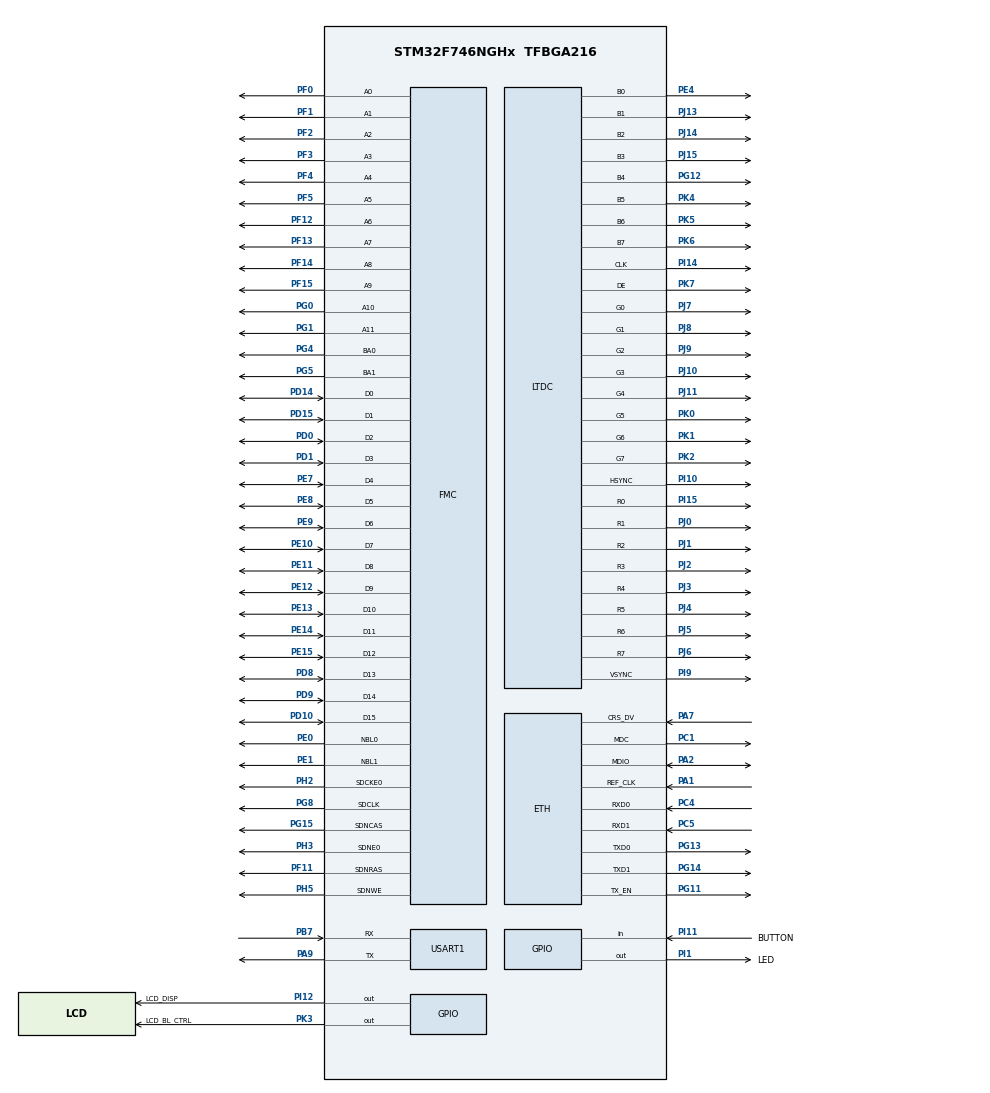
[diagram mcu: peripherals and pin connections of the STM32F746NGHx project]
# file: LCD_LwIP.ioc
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ETH.MACAddr=00\:80\:E1\:00\:00\:44
ETH.MediaInterface=ETH_MEDIA_INTERFACE_RMII
ETH.PhyAddress=0
LTDC.ActiveH=272
LTDC.ActiveW=480
LTDC.Alpha_L0=255
LTDC.Alpha_L1=255
LTDC.BlendingFactor1_L0=LTDC_BLENDING_FACTOR1_PAxCA
LTDC.BlendingFactor1_L1=LTDC_BLENDING_FACTOR1_PAxCA
LTDC.BlendingFactor2_L0=LTDC_BLENDING_FACTOR2_PAxCA
LTDC.BlendingFactor2_L1=LTDC_BLENDING_FACTOR2_PAxCA
LTDC.Green=255
LTDC.HBP=13
LTDC.HFP=32
LTDC.HSync=41
LTDC.ImageHeight_L0=272
LTDC.ImageHeight_L1=272
LTDC.ImageWidth_L0=480
LTDC.ImageWidth_L1=480
LTDC.PixelFormat_L0=LTDC_PIXEL_FORMAT_ARGB1555
LTDC.PixelFormat_L1=LTDC_PIXEL_FORMAT_ARGB1555
LTDC.VSync=10
LTDC.WindowX1_L0=480
LTDC.WindowX1_L1=480
LTDC.WindowY1_L0=272
LTDC.WindowY1_L1=272
LWIP.IP_ADDRESS=192.168.069.010
LWIP.LWIP_DHCP=0
LWIP.NETMASK_ADDRESS=255.255.255.000
LWIP.Version=v2.0.3_Cube
Mcu.Family=STM32F7
Mcu.Name=STM32F746NGHx
Mcu.Package=TFBGA216
NVIC.PriorityGroup=NVIC_PRIORITYGROUP_4
PA1.Mode=RMII
PA1.Signal=ETH_REF_CLK
PA2.Mode=RMII
PA2.Signal=ETH_MDIO
PA7.Mode=RMII
PA7.Signal=ETH_CRS_DV
PA9.Mode=Asynchronous
PA9.Signal=USART1_TX
PB7.Mode=Asynchronous
PB7.Signal=USART1_RX
PC1.Mode=RMII
PC1.Signal=ETH_MDC
PC14/OSC32_IN.Mode=LSE-External-Oscillator
PC14/OSC32_IN.Signal=RCC_OSC32_IN
PC15/OSC32_OUT.Mode=LSE-External-Oscillator
PC15/OSC32_OUT.Signal=RCC_OSC32_OUT
PC4.Mode=RMII
PC4.Signal=ETH_RXD0
PC5.Mode=RMII
PC5.Signal=ETH_RXD1
PD0.Signal=FMC_D2_DA2
PD1.Signal=FMC_D3_DA3
PD10.Signal=FMC_D15_DA15
PD14.Signal=FMC_D0_DA0
PD15.Signal=FMC_D1_DA1
PD8.Signal=FMC_D13_DA13
PD9.Signal=FMC_D14_DA14
PE0.Signal=FMC_NBL0
PE1.Signal=FMC_NBL1
PE10.Signal=FMC_D7_DA7
PE11.Signal=FMC_D8_DA8
PE12.Signal=FMC_D9_DA9
PE13.Signal=FMC_D10_DA10
PE14.Signal=FMC_D11_DA11
PE15.Signal=FMC_D12_DA12
PE4.Mode=RGB888
PE4.Signal=LTDC_B0
PE7.Signal=FMC_D4_DA4
PE8.Signal=FMC_D5_DA5
PE9.Signal=FMC_D6_DA6
PF0.Signal=FMC_A0
PF1.Signal=FMC_A1
PF11.Signal=FMC_SDNRAS
PF12.Signal=FMC_A6
PF13.Signal=FMC_A7
PF14.Signal=FMC_A8
PF15.Signal=FMC_A9
PF2.Signal=FMC_A2
PF3.Signal=FMC_A3
PF4.Signal=FMC_A4
PF5.Signal=FMC_A5
PG0.Signal=FMC_A10
PG1.Signal=FMC_A11
PG11.Mode=RMII
PG11.Signal=ETH_TX_EN
PG12.Mode=RGB888
PG12.Signal=LTDC_B4
PG13.Mode=RMII
PG13.Signal=ETH_TXD0
PG14.Mode=RMII
PG14.Signal=ETH_TXD1
PG15.Signal=FMC_SDNCAS
PG4.Signal=FMC_A14_BA0
PG5.Signal=FMC_A15_BA1
PG8.Signal=FMC_SDCLK
PH0/OSC_IN.Mode=HSE-External-Oscillator
PH0/OSC_IN.Signal=RCC_OSC_IN
PH1/OSC_OUT.Mode=HSE-External-Oscillator
PH1/OSC_OUT.Signal=RCC_OSC_OUT
PH2.Mode=SdramChipSelect1_1
PH2.Signal=FMC_SDCKE0
PH3.Mode=SdramChipSelect1_1
PH3.Signal=FMC_SDNE0
PH5.Signal=FMC_SDNWE
PI1.GPIO_Label=LED
PI1.Signal=GPIO_Output
PI10.Mode=RGB888
PI10.Signal=LTDC_HSYNC
PI11.GPIO_Label=BUTTON
PI11.Signal=GPIO_Input
PI12.GPIO_Label=LCD_DISP
PI12.Signal=GPIO_Output
PI14.Mode=RGB888
PI14.Signal=LTDC_CLK
PI15.Mode=RGB888
PI15.Signal=LTDC_R0
PI9.Mode=RGB888
PI9.Signal=LTDC_VSYNC
PJ0.Mode=RGB888
PJ0.Signal=LTDC_R1
PJ1.Mode=RGB888
PJ1.Signal=LTDC_R2
PJ10.Mode=RGB888
PJ10.Signal=LTDC_G3
PJ11.Mode=RGB888
PJ11.Signal=LTDC_G4
PJ13.Mode=RGB888
PJ13.Signal=LTDC_B1
PJ14.Mode=RGB888
PJ14.Signal=LTDC_B2
PJ15.Mode=RGB888
PJ15.Signal=LTDC_B3
PJ2.Mode=RGB888
PJ2.Signal=LTDC_R3
PJ3.Mode=RGB888
PJ3.Signal=LTDC_R4
PJ4.Mode=RGB888
PJ4.Signal=LTDC_R5
PJ5.Mode=RGB888
PJ5.Signal=LTDC_R6
PJ6.Mode=RGB888
PJ6.Signal=LTDC_R7
PJ7.Mode=RGB888
PJ7.Signal=LTDC_G0
PJ8.Mode=RGB888
PJ8.Signal=LTDC_G1
PJ9.Mode=RGB888
PJ9.Signal=LTDC_G2
PK0.Mode=RGB888
PK0.Signal=LTDC_G5
PK1.Mode=RGB888
PK1.Signal=LTDC_G6
PK2.Mode=RGB888
PK2.Signal=LTDC_G7
PK3.GPIO_Label=LCD_BL_CTRL
PK3.Signal=GPIO_Output
PK4.Mode=RGB888
PK4.Signal=LTDC_B5
PK5.Mode=RGB888
PK5.Signal=LTDC_B6
PK6.Mode=RGB888
PK6.Signal=LTDC_B7
PK7.Mode=RGB888
PK7.Signal=LTDC_DE
ProjectManager.HeapSize=0x200
ProjectManager.StackSize=0x400
ProjectManager.TargetToolchain=SW4STM32
RCC.AHBFreq_Value=200000000
RCC.APB1CLKDivider=RCC_HCLK_DIV4
RCC.APB1Freq_Value=50000000
RCC.APB1TimFreq_Value=100000000
RCC.APB2CLKDivider=RCC_HCLK_DIV2
RCC.APB2Freq_Value=100000000
RCC.APB2TimFreq_Value=200000000
RCC.CortexFreq_Value=200000000
RCC.HCLKFreq_Value=200000000
RCC.HSE_VALUE=25000000
RCC.HSI_VALUE=16000000
RCC.PLLM=25
RCC.PLLN=400
RCC.PLLSAIR=5
RCC.PLLSAIRDiv=RCC_PLLSAIDIVR_4
RCC.PLLSourceVirtual=RCC_PLLSOURCE_HSE
RCC.SYSCLKFreq_VALUE=200000000
RCC.SYSCLKSource=RCC_SYSCLKSOURCE_PLLCLK
RCC.USBFreq_Value=200000000
RCC.VCOOutputFreq_Value=400000000
SH.FMC_A0.0=FMC_A0,12b-sda1
SH.FMC_A1.0=FMC_A1,12b-sda1
SH.FMC_A10.0=FMC_A10,12b-sda1
SH.FMC_A11.0=FMC_A11,12b-sda1
SH.FMC_A14_BA0.0=FMC_BA0,FourSdramBanks1
SH.FMC_A15_BA1.0=FMC_BA1,FourSdramBanks1
SH.FMC_A2.0=FMC_A2,12b-sda1
SH.FMC_A3.0=FMC_A3,12b-sda1
SH.FMC_A4.0=FMC_A4,12b-sda1
SH.FMC_A5.0=FMC_A5,12b-sda1
SH.FMC_A6.0=FMC_A6,12b-sda1
SH.FMC_A7.0=FMC_A7,12b-sda1
SH.FMC_A8.0=FMC_A8,12b-sda1
SH.FMC_A9.0=FMC_A9,12b-sda1
SH.FMC_D0_DA0.0=FMC_D0,sd-16b-d1
SH.FMC_D10_DA10.0=FMC_D10,sd-16b-d1
SH.FMC_D11_DA11.0=FMC_D11,sd-16b-d1
SH.FMC_D12_DA12.0=FMC_D12,sd-16b-d1
SH.FMC_D13_DA13.0=FMC_D13,sd-16b-d1
SH.FMC_D14_DA14.0=FMC_D14,sd-16b-d1
SH.FMC_D15_DA15.0=FMC_D15,sd-16b-d1
SH.FMC_D1_DA1.0=FMC_D1,sd-16b-d1
SH.FMC_D2_DA2.0=FMC_D2,sd-16b-d1
SH.FMC_D3_DA3.0=FMC_D3,sd-16b-d1
SH.FMC_D4_DA4.0=FMC_D4,sd-16b-d1
SH.FMC_D5_DA5.0=FMC_D5,sd-16b-d1
SH.FMC_D6_DA6.0=FMC_D6,sd-16b-d1
SH.FMC_D7_DA7.0=FMC_D7,sd-16b-d1
SH.FMC_D8_DA8.0=FMC_D8,sd-16b-d1
SH.FMC_D9_DA9.0=FMC_D9,sd-16b-d1
SH.FMC_NBL0.0=FMC_NBL0,Sd2ByteEnable1
SH.FMC_NBL1.0=FMC_NBL1,Sd2ByteEnable1
SH.FMC_SDCLK.0=FMC_SDCLK,12b-sda1
SH.FMC_SDNCAS.0=FMC_SDNCAS,12b-sda1
SH.FMC_SDNRAS.0=FMC_SDNRAS,12b-sda1
SH.FMC_SDNWE.0=FMC_SDNWE,12b-sda1
USART1.VirtualMode=VM_ASYNC
USART1.VirtualMode-Asynchronous=VM_ASYNC
USART1.WordLength=WORDLENGTH_8B
VP_DMA2D_VS_DMA2D.Mode=DMA2D_Activate
VP_LWIP_VS_Enabled.Mode=Enabled
board=STM32F746G-DISCO

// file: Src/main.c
/**
= Titel van het project: Game of Life =

== door:  Vermeulen Gijs ==

== Korte beschrijving ==
Conway's game of life soms wel life genoemd is een cellulaire automaat.

Deze bevind zich in een 2 dimensionaal raster met vierkante "cellen" die levend of dood kunnen zijn
en die zich volgens vastgelegde regels ontwikkelen en daarbij patronen kunnen vormen.

Dit algoritme volgt 3 hoofd regels:
	Als een levende cel door 2 of 3 levende buurcellen omgeven wordt blijft deze cel leven
	Als een levende cel door 4 of meer levende buurcellen omgeven wordt gaat deze cel dood
	Als een dode cel door precies 3 gekleurde buurcellen omgeven wordt gaat deze cel leven

Dit algoritme heb ik in labview gemaakt.
Het labview programma gaat als server werken en het embedded systeem gaat hier via TCP/IP data van halen en weergeven op zijn LCD.
De client kan ook zelf dingen naar de server sturen.
	- via knoppen kunnen een aantal vaste patronen verstuurd worden
	- via de "eigen "knop" kan men iets in de server applicatie tekenen of als text string ingeven.
Oneindig veel plezier !
== Libs, compiler en apps ==

 - lwip version LwIP V2.0.3 version ( de versie van uit het labo bestand )
 - CubeMX version 4.27.0
 - System workbench (SW4STM32) FW_F7_V1.15.0
 - Labview 2013

== Bestanden aangemaakt/aangepast ==

   Aangepaste bestanden:
	- LCD_LwIP  ( gestart van het bestand op canvas )
   Aangemaakte bestanden:
	- Labview programma ( server )
	- alle afbeeldingen gebruikt in het project ( paint )

== Opmerkingen ==
voor het labview programma te starten :
					- kan op zich werken :
						- zie dat communicatie uit staat
						- zie dat milliseconds to wait minstens op 500 staat
						- begin het programma door via het keuze menu data in de array te sturen.
						( de keuzes :init, next , niks en communicatie versturen geen data in de array !)
						- ( hij zet data altijd in het midden van de array )
						- ( bij eigen zet hij de data in het begin via de eigen array in het programma
						- LET THE GAME BEGIN !
					- als server :
						- zie dat communicatie aan staat ( knop )
						- zie dat milliseconds to wait op 0 staat
						- zie dat grote op 20 ( server verstuurd 1 info pakket en 1 data pakket )tot 30 staat ( server verstuurd 1 info pakket en 2 data pakketten )
						( als we te groot gaan kan LWIP de data niet aan en verliezen we pakketten of worden pakketten random genegeerd )
						- zet de client nu aan ( hij connecteerd beter als je voor op start te klikken eerst is op stop klikt )
						- op de client kan je terwijl het programma bezig is data in de array sturen via de knoppen.
						- De server gaat maar 1 keer rekening houden met de data dat een knop verstuurd ookal blijft de knop actief ( de knop op de LCD licht groen op)
						- je kan maar 1 knop actief hebben tegelijkertijd
						- ( door nog eens op de knop te duwen desactiveer je de knop )
						- soms als je te laat drukt zal er nog een fase tussen zitten ( hangt af van de timing wanneer je klikt en wanneer de pakketten verstuurd worden)
						- LET THE FUN BEGIN

De server loopt altijd 1 fase voor op de client.
( als de client zegt trying to connect kan je best eens op stop drukken en dan terug op start drukken , ik heb ondervonden dat hij dan direct binnen raakt )

== Bronvermeldingen ==
https://en.wikipedia.org/wiki/Conway%27s_Game_of_Life

== Optioneel: Extra's ==

  */
#include "main.h"
#include "stm32f7xx_hal.h"
#include "lwip.h"
#include <errno.h>
#include <sys/stat.h>
#include <sys/times.h>
#include <sys/unistd.h>
#include <tcp.h>

/* USER CODE BEGIN Includes */

#include<stdio.h>
#include<stdlib.h>
#include<stdint.h>
#include "stm32746g_discovery.h"
#include "stm32746g_discovery_lcd.h"
#include "stm32746g_discovery_sdram.h"
#include "stm32746g_discovery_ts.h"

// image data
#include "stop_knop_data.h"
#include "start_KNOP_data.h"
#include "levende_cel_data.h"
#include "dode_cel_data.h"
#include "Block_knop_inactive_data.h"
#include "custom_knop_inactive_data.h"
#include "GLIDER_knop_inactive_data.h"
#include "knop_active_data.h"
#include "LWSS_knop_inactive_data.h"
#include "PULSAR_knop_inactive_data.h"
#include "INIT_knop_inactive_data.h"
/* USER CODE END Includes */

DMA2D_HandleTypeDef hdma2d;

LTDC_HandleTypeDef hltdc;

UART_HandleTypeDef huart1;

SDRAM_HandleTypeDef hsdram1;

/* USER CODE BEGIN PV */
/* Private variables ---------------------------------------------------------*/

// globale variabelen

char x_tcp_buffer[1024];
uint8_t uc_Closed = 0;
uint8_t uc_Gcounter = 0;

uint8_t uc_start = 1;
uint8_t uc_Data = 0;
uint16_t us_Glen = 0;
int16_t us_Ga = 0;			// als er meerdere data paketten zijn de x waarde bijhouden
int16_t us_Gj = 0;			// als er meerdere data paketten zijn de y waarde bijhouden

// defines

#define x10  10
#define x85  85
#define y20  20
#define y60  60
#define y100 100
#define y140 140
#define y180 180
#define y220 220

#define PORT_SERVER 20
#define PORT_CLIENT 40000

/* USER CODE END PV */

void SystemClock_Config( void );
static void MX_GPIO_Init( void );
static void MX_LTDC_Init( void );
static void MX_USART1_UART_Init( void );
static void MX_DMA2D_Init( void );
static void MX_FMC_Init( void );

/* USER CODE BEGIN PFP */
/* Private function prototypes -----------------------------------------------*/
static void prvdraw( uint16_t, uint8_t );
static uint8_t ucomzetten( uint16_t );

/* ---------------------------------------------------------------------------------*/
/* USER CODE END PFP */

/* USER CODE BEGIN 0 */

int16_t _write( int16_t us_file, char *ptr, int16_t us_len1 )
{
    HAL_StatusTypeDef xStatus;
    switch (us_file) {
    case STDOUT_FILENO: /*stdout*/
		xStatus = HAL_UART_Transmit(&huart1, (uint8_t*)ptr, us_len1, HAL_MAX_DELAY);
		if ( xStatus != HAL_OK ) {
			errno = EIO;
			return -1;
		}
        break;
    case STDERR_FILENO: /* stderr */
		xStatus = HAL_UART_Transmit(&huart1, (uint8_t*)ptr, us_len1, HAL_MAX_DELAY);
		if ( xStatus != HAL_OK ) {
			errno = EIO;
			return -1;
		}
        break;
    default:
        errno = EBADF;
        return -1;
    }
    return us_len1;
}
/* ---------------------------------------------------------------------------------*/
static void Close (struct tcp_pcb *pcb )
{

    tcp_close(pcb);
    BSP_LCD_ClearStringLine(0);
	BSP_LCD_DisplayStringAt(0, 0, (uint8_t*) "Disconnected", CENTER_MODE);
	// globale waardes goed zetten voor de volgende connectie
    uc_Gcounter = 0;
    us_Glen = 0;
    us_Ga = 0;
    us_Gj = 0;
    uc_start = 1;
}
/* ---------------------------------------------------------------------------------*/
static err_t Ontvangen( void *arg, struct tcp_pcb *pcb, struct pbuf *p, err_t err )
{
	uint16_t us_Teller;
    uint16_t us_len;
    char *pc;
    uc_Gcounter++;
    LWIP_UNUSED_ARG( arg );
    if ( err == ERR_OK && p != NULL )			// er is geen error en er zit data in de databuffer
    {
    	tcp_recved( pcb, p->tot_len );
    	printf("stuur ack naar server\r\n");
    	pc = (char *)p->payload;
    	us_len =p->tot_len;
    	for( us_Teller = 0; us_Teller<us_len; us_Teller++ )
    	{
    		x_tcp_buffer[us_Teller] = pc[us_Teller];
    	}
    	prvdraw(us_len, uc_Gcounter);
    }
    else									  // stel er gaat iets mis ( een error bv ) maak de buffer vrij
    {
    	pbuf_free( p );
    }

    pbuf_free( p );

    if( err == ERR_OK && p == NULL )			// er is geen error en de databuffer is leeg gemaakt sluit de connectie
    {
        Close( pcb );
    }
    return ERR_OK;
}
/* ---------------------------------------------------------------------------------*/
static err_t Connected( void *arg, struct tcp_pcb *pcb, err_t err )

{
    LWIP_UNUSED_ARG( arg );
    LWIP_UNUSED_ARG( err );
    if ( err == ERR_OK )
    {
    	printf("connected\r\n");
    	BSP_LCD_DisplayStringAt(0, 0, (uint8_t*) "connected to the server", CENTER_MODE);
    	if ( uc_Data == 0 )
    	{
    		tcp_write( pcb, "0", 1, 0 );
    	}
    	if ( uc_Data == 1 )
    	{
    		tcp_write( pcb, "1", 1, 0 );
    	}
    	if ( uc_Data == 2 )
    	{
    		tcp_write( pcb, "2", 1, 0 );
    	}
    	if ( uc_Data == 3 )
    	{
    		tcp_write( pcb, "3", 1, 0 );
    	}
    	if ( uc_Data == 4 )
    	{
    		tcp_write( pcb, "4", 1, 0 );
    	}
    	if ( uc_Data == 5 )
    	{
    		tcp_write( pcb, "5", 1, 0 );
    	}
    	if ( uc_Data == 6 )
    	{
    		tcp_write( pcb, "6", 1, 0 );
    	}
    	if ( uc_Data == 7 )
    	{
    		tcp_write( pcb, "7", 1, 0 );
    	}
    	tcp_sent( pcb, NULL );
    	tcp_recv( pcb, Ontvangen );
    }

    if ( err == ERR_MEM )
    {
    	printf("Oops ran out of memory\r\n");
    	Close( pcb );
    }

    return ERR_OK;
}
/* ---------------------------------------------------------------------------------*/
/* functie draw
 * Gaat alle data op het LCD schrijven
 * pakket 1 is geen data pakket en moet worden verwerkt door de functie omzetten
 * pakket 2 en hoger zijn data pakketten
 * param grootte : hoeveel data er in het pakket zit
 * param pakket : het hoeveelste pakket data we aan zitten
 */
 void prvdraw( uint16_t us_Grootte, uint8_t us_pakket )
{
	 uint16_t us_Counter;
	 uint16_t us_X = 170;			// moet groter zijn dan 8 bit !!
	 uint16_t us_Y = 32;			// moet groter zijn dan 8 bit !!
	 uint16_t us_Volgend = 0;
	 uint8_t uc_start_x = 170;
	 uint8_t uc_start_y = 32;

	 if ( us_pakket == 1)
	 {
		 us_Glen = ucomzetten(us_Grootte);
	 }
	 // het tweede pakket is het DATA pakket
	 if ( us_pakket > 1  )
	 {
 		 // vanaf pakket 3 komt moet hij rekening houden met het punt waar pakket 2 is gestopt met tekenen
 		 //: waarde zit in us_Ga deze gaan we lokaal bijhouden in
		 us_Volgend = us_Ga;
	 	 for (us_Counter = us_Volgend ; us_Counter < us_Grootte + us_Volgend ; us_Counter++)
	 	 {
	 		    if ( ( us_Counter > 0) && (us_Counter % us_Glen == 0 ) )
	 		    {
	 		    	// als de counter deelbaar is door de lengte en groter dan 0 moet er naar de volgende lijn gegaan worden
	 		    	us_Ga = 0;
	 		    	us_Gj++;
	 		    }

	 		    us_X = uc_start_x + us_Ga * 8;	   // X coodinaat
	 		    us_Y = uc_start_y + us_Gj * 8;     // Y coordinaat

	 			if ( x_tcp_buffer[us_Counter - us_Volgend] == '0' )
	 	 		{
	 	 			WDA_LCD_DrawBitmap((void * ) DODE_CEL_DATA,us_X,us_Y,DODE_CEL_DATA_X_PIXEL,DODE_CEL_DATA_Y_PIXEL,DODE_CEL_DATA_FORMAT);
	 	 		}
	 	 		if ( x_tcp_buffer[us_Counter - us_Volgend] == '1' )
	 	 		{
	 	 			WDA_LCD_DrawBitmap((void * ) LEVENDE_CEL_DATA,us_X,us_Y ,LEVENDE_CEL_DATA_X_PIXEL,LEVENDE_CEL_DATA_Y_PIXEL,LEVENDE_CEL_DATA_FORMAT);
	 	 		}
	 		   	us_Ga++;
	 	 }
	 }
}
 /* ---------------------------------------------------------------------------------*/
 /*	Functie omzetten
  * Gaat de string uit het eerste data pakket van de server omzetten in een numerieke waarde
  * param Grootte : Hoeveel data er in het pakket zit
  * ret : in numerieke waarde hoe lang de rijen zijn
  */
uint8_t ucomzetten( uint16_t us_Grootte )
{
	 // het eerste pakket zit de grootte van de array in
	 // deze staat in ASCI code dus moeten we omzetten in een numeriek waarde
	 uint16_t us_i =0 ;
	 uint8_t uc_a = 0;
	 uint8_t uc_ASCI = 0;
	 uint8_t uc_waardes[10] = {0,1,2,3,4,5,6,7,8,9};
	 //0: ASCI 48
	 //1: ASCI 49
	 //2: ASCI 50
	 //3: ASCI 51
	 //4: ASCI 52
	 //5: ASCI 53
	 //6: ASCI 54
	 //7: ASCI 55
	 //8: ASCI 56
	 //9: ASCI 57
	 for ( us_i = 0 ; us_i < us_Grootte; us_i++ )
	 {
	 	 uc_ASCI =  (uint8_t)(x_tcp_buffer[us_i]);
	 	 switch (uc_ASCI)
	 	{
	 		 case 48 :	//0
	 		 if ( us_i == 0 && us_Grootte > 1 )
	 		{
	 			 uc_a += 10 * uc_waardes[0];
	 		 }
	 				 if ( us_i == 0 && us_Grootte <= 1 )
	 				 {
	 					 uc_a +=  + uc_waardes[0];
	 				 }
	 				 if ( us_i == 1 )
	 				 {
	 					uc_a += 1 * uc_waardes[0];
	 				 }
	 				 break;
	 			 case 49 :	//1
	 				 if ( us_i == 0 && us_Grootte > 1 )
	 				 {
	 					 uc_a += 10 * uc_waardes[1];
	 				 }
	 				 if ( us_i == 0 && us_Grootte <= 1 )
	 				 {
	 					 uc_a += + uc_waardes[1];
	 				 }
	 				 if ( us_i == 1 )
	 				 {
	 					 uc_a += 1 * uc_waardes[1];
	 				 }
	 				 break;
	 			 case 50 :	//2
	 				 if ( us_i == 0 && us_Grootte > 1 )
	 				 {
	 					 uc_a += 10 * uc_waardes[2];
	 				 }
	 				 if ( us_i == 0 && us_Grootte <= 1 )
	 				 {
	 					 uc_a += + uc_waardes[2];
	 				 }
	 				 if ( us_i == 1 )
	 				 {
	 					 uc_a += 1 * uc_waardes[2];
	 				 }
	 				 break;
	 			 case 51 :	//3
	 				 if ( us_i == 0 && us_Grootte > 1 )
	 				 {
	 					 uc_a += 10 * uc_waardes[3];
	 				 }
	 				 if ( us_i == 0 && us_Grootte <= 1 )
	 				 {
	 					 uc_a += + uc_waardes[3];
	 				 }
	 				 if ( us_i == 1 && us_Grootte > 1 )
	 				 {
	 					 uc_a += 1 * uc_waardes[3];
	 				 }
	 				 break;
	 			 case 52 :	//4
	 				 if ( us_i == 0 && us_Grootte > 1 )
	 				 {
	 					 uc_a += 10 * uc_waardes[4];
	 				 }
	 				 if ( us_i == 0 && us_Grootte <= 1 )
	 				 {
	 					 uc_a += + uc_waardes[4];
	 				 }
	 				 if ( us_i == 1 && us_Grootte > 1 )
	 				 {
	 					 uc_a += 1 * uc_waardes[4];
	 				 }
	 				 break;
	 			 case 53 :	//5
	 				 if ( us_i == 0 && us_Grootte > 1 )
	 				 {
	 					 uc_a += 10 * uc_waardes[5];
	 				 }
	 				 if ( us_i == 0 && us_Grootte <= 1 )
	 				 {
	 					 uc_a =  + uc_waardes[5];
	 				 }
	 				 if ( us_i == 1 )
	 				 {
	 					 uc_a += 1 * uc_waardes[5];
	 				 }
	 				 break;
	 			 case 54 :	//6
	 				 if ( us_i == 0 && us_Grootte > 1 )
	 				 {
	 					 uc_a += 10 * uc_waardes[6];
	 				 }
	 				 if ( us_i == 0 && us_Grootte <= 1 )
	 				 {
	 					 uc_a +=  + uc_waardes[6];
	 				 }
	 				 if ( us_i == 1 )
	 				 {
	 					 uc_a += 1 * uc_waardes[6];
	 				 }
	 				 break;
	 			 case 55 :	//7
	 				 if ( us_i == 0 && us_Grootte > 1 )
	 				 {
	 					 uc_a += 10 * uc_waardes[7];
	 				 }
	 				 if ( us_i == 0 && us_Grootte <= 1 )
	 				 {
	 					 uc_a +=  + uc_waardes[7];
	 				 }
	 				 if ( us_i == 1 )
	 				 {
	 					 uc_a += 1 * uc_waardes[7];
	 				 }
	 				 break;
	 			 case 56 :	//8
	 				 if ( us_i == 0 && us_Grootte > 1 )
	 				 {
	 					 uc_a += 10 * uc_waardes[8];
	 				 }
	 				 if ( us_i == 0 && us_Grootte <= 1 )
	 				 {
	 					 uc_a += + uc_waardes[8];
	 				 }
	 				 if ( us_i == 1 )
	 				 {
	 					 uc_a += 1 * uc_waardes[8];
	 				 }
	 				 break;
	 			 case 57 :	//9
	 				 if ( us_i == 0 && us_Grootte > 1 )
	 				 {
	 					 uc_a += 10 * uc_waardes[9];
	 				 }
	 				 if ( us_i == 0 && us_Grootte <= 1 )
	 				 {
	 					 uc_a +=  + uc_waardes[9];
	 				 }
	 				 if ( us_i == 1 )
	 				 {
	 					 uc_a += 1 * uc_waardes[9];
	 				 }
	 				 break;
	 			 }
	 }
	 return uc_a;
 }
/* ---------------------------------------------------------------------------------*/
 /* USER CODE END 0 */

int main( void )
{
  /* USER CODE BEGIN 1 */
	uint8_t uc_keuze = 0;
  /* USER CODE END 1 */

  /* MCU Configuration----------------------------------------------------------*/

  /* Reset of all peripherals, Initializes the Flash interface and the Systick. */
  HAL_Init();

  /* Configure the system clock */
  SystemClock_Config();

  /* Initialize all configured peripherals */
  MX_GPIO_Init();
  MX_LTDC_Init();
  MX_USART1_UART_Init();
  MX_DMA2D_Init();
  MX_FMC_Init();
  MX_LWIP_Init();
  /* USER CODE BEGIN 2 */

  /* LCD Initialization */
    BSP_LCD_Init();
    BSP_LCD_LayerDefaultInit(1, LCD_FB_START_ADDRESS);
    BSP_LCD_LayerDefaultInit(0, LCD_FB_START_ADDRESS+(480*272*4));
    /* Enable the LCD */
    BSP_LCD_DisplayOn();
    /* Select the LCD Background Layer  */
    BSP_LCD_SelectLayer(0);
    /* Clear the Background Layer */
    BSP_LCD_Clear(LCD_COLOR_BLACK);
    BSP_LCD_SelectLayer(1);
    /* Clear the foreground Layer */
    BSP_LCD_Clear(LCD_COLOR_BLACK);
    /* Some sign */
    BSP_LCD_SetTextColor(LCD_COLOR_RED);
    BSP_LCD_SetFont(&Font12);
    BSP_LCD_DisplayStringAt(0, 0, (uint8_t*) "Welcome", CENTER_MODE);

    BSP_TS_Init(480,272);

    // TEKEN DE KNOPPEN
   WDA_LCD_DrawBitmap((void * ) START_KNOP_DATA,x10,y20,START_KNOP_DATA_X_PIXEL,START_KNOP_DATA_Y_PIXEL,START_KNOP_DATA_FORMAT);	// startknop
   WDA_LCD_DrawBitmap((void * ) STOP_KNOP_DATA,x10,y60,STOP_KNOP_DATA_X_PIXEL,STOP_KNOP_DATA_Y_PIXEL,STOP_KNOP_DATA_FORMAT);		// stopknop
   WDA_LCD_DrawBitmap((void * ) BLOCK_KNOP_INACTIVE_DATA,x10,y100,BLOCK_KNOP_INACTIVE_DATA_X_PIXEL,BLOCK_KNOP_INACTIVE_DATA_Y_PIXEL ,BLOCK_KNOP_INACTIVE_DATA_FORMAT); // keuzeknop 1
   WDA_LCD_DrawBitmap((void * ) GLIDER_KNOP_INACTIVE_DATA,x10,y140,GLIDER_KNOP_INACTIVE_DATA_X_PIXEL,GLIDER_KNOP_INACTIVE_DATA_Y_PIXEL,GLIDER_KNOP_INACTIVE_DATA_FORMAT); // keuzeknop 2
   WDA_LCD_DrawBitmap((void * ) CUSTOM_KNOP_INACTIVE_DATA,x10,y180,CUSTOM_KNOP_INACTIVE_DATA_X_PIXEL,CUSTOM_KNOP_INACTIVE_DATA_Y_PIXEL,CUSTOM_KNOP_INACTIVE_DATA_FORMAT); // keuzeknop 3
   WDA_LCD_DrawBitmap((void * ) LWSS_KNOP_INACTIVE_DATA,x10,y220,LWSS_KNOP_INACTIVE_DATA_X_PIXEL,LWSS_KNOP_INACTIVE_DATA_Y_PIXEL,LWSS_KNOP_INACTIVE_DATA_FORMAT); // keuzeknop 4
   WDA_LCD_DrawBitmap((void * ) PULSAR_KNOP_INACTIVE_DATA,x85,y100,PULSAR_KNOP_INACTIVE_DATA_X_PIXEL,PULSAR_KNOP_INACTIVE_DATA_Y_PIXEL,PULSAR_KNOP_INACTIVE_DATA_FORMAT); // keuzeknop 5
   WDA_LCD_DrawBitmap((void * ) INIT_KNOP_INACTIVE_DATA,x85,y140,INIT_KNOP_INACTIVE_DATA_X_PIXEL,INIT_KNOP_INACTIVE_DATA_Y_PIXEL,INIT_KNOP_INACTIVE_DATA_FORMAT); // keuzeknop 6

    // LWIP init
    struct tcp_pcb *tcp_connectie;
    ip_addr_t ip_addr_serverIp;
    ip_addr_t ip_addr_clientIp;

    IP4_ADDR(&ip_addr_serverIp,192,168,69,11);
    IP4_ADDR(&ip_addr_clientIp,192,168,69,10);

  /* USER CODE END 2 */

  /* Infinite loop */
  while (1)
  {

  /* USER CODE BEGIN 3 */
	  MX_LWIP_Process();

	  TS_StateTypeDef TS_State;
	  BSP_TS_GetState(&TS_State);
	  // startknop
	  if ( ( ( uc_start == 1) && ( uc_Closed == 1) ) || ( ( ( ( ( ( uc_start == 1 ) &&  ( TS_State.touchDetected ) ) &&  ( TS_State.touchX[0] >= 10  ) ) && ( TS_State.touchX[0] <= 75 ) ) && ( TS_State.touchY[0] >= 20 ) ) && ( TS_State.touchY[0] <= 55) ) )
	 	{
	 		printf("start\r\n");
	 		BSP_LCD_ClearStringLine(0);
	 		BSP_LCD_DisplayStringAt(0, 0, ( uint8_t* ) "Trying to connect", CENTER_MODE);
			uc_start = 0;		// het mogelijk maken dat we maar 1 verbinding tegelijkertijd kunnen hebben
			uc_Closed = 1;		// het mogelijk maken om de verbinding automatisch opnieuw te laten starten
			tcp_connectie = tcp_new();	// nieuwe verbinding initialiseren
			tcp_bind(tcp_connectie,&ip_addr_clientIp , PORT_CLIENT);
			tcp_arg(tcp_connectie,NULL);
			tcp_connect(tcp_connectie, &ip_addr_serverIp, PORT_SERVER, Connected);
	 	 }

	  // stopknop
	  if ( ( ( ( ( ( uc_Closed == 1 ) && (TS_State.touchDetected ) ) && ( TS_State.touchX[0] >= 10  ) ) && ( TS_State.touchX[0] <= 75 ) ) && ( TS_State.touchY[0] >= 60 ) ) && ( TS_State.touchY[0] <= 95 )  )
	 	{
		  // om de connectie op een mooie manier te sluiten
		  // gaan we nog 1 keer connecteren en 1 keer data krijgen
		  	  uc_Closed = 0;
	 		  printf("stop\r\n");
		      tcp_connectie = tcp_new();
		      tcp_bind(tcp_connectie,&ip_addr_clientIp , PORT_CLIENT);
		      tcp_arg(tcp_connectie,NULL);
	 		  Close(tcp_connectie);

	 		 BSP_LCD_ClearStringLine(0);
	 		 BSP_LCD_DisplayStringAt(0, 0, (uint8_t*) "trying to disconnect", CENTER_MODE);

	 	 }
	  // keuze knop Block
	  if ( ( ( uc_keuze == 0 ) || ( uc_Data == 1 ) ) && ( ( ( ( TS_State.touchDetected ) && ( TS_State.touchX[0] >= 10  ) ) &&  ( TS_State.touchX[0] <= 75 ) ) && ( TS_State.touchY[0] >= 100 ) ) && ( TS_State.touchY[0] <= 135 ) )
	  {
		  HAL_Delay(100);
		  BSP_TS_GetState(&TS_State);
		  if (( TS_State.touchDetected ) == 0 )
		  {
			  if ( uc_keuze == 0)
			  {
				  uc_keuze = 1;
				  uc_Data =  1;
				  WDA_LCD_DrawBitmap((void * ) KNOP_ACTIVE_DATA,x10,y100,KNOP_ACTIVE_DATA_X_PIXEL,KNOP_ACTIVE_DATA_Y_PIXEL ,KNOP_ACTIVE_DATA_FORMAT); // keuzeknop 1
			  }
			  else if ( uc_keuze == 1)
			  {
				  uc_Data = 0;
				  uc_keuze = 0;
				  WDA_LCD_DrawBitmap((void * ) BLOCK_KNOP_INACTIVE_DATA,x10,y100,BLOCK_KNOP_INACTIVE_DATA_X_PIXEL,BLOCK_KNOP_INACTIVE_DATA_Y_PIXEL ,BLOCK_KNOP_INACTIVE_DATA_FORMAT); // keuzeknop 1
			  }
			  else
			  {

			  }
		  }
		  HAL_Delay(100);
	  }

	  // keuze knop GLIDER
	  if ( ( ( uc_keuze == 0 ) || ( uc_Data == 3 ) ) && ( ( ( (TS_State.touchDetected ) && ( TS_State.touchX[0] >= 10  ) ) && ( TS_State.touchX[0] <= 75 ) ) && ( TS_State.touchY[0] >= 140 ) ) && ( TS_State.touchY[0] <= 175 ) )
	  {
		  HAL_Delay(100);
		  BSP_TS_GetState(&TS_State);
		  if ( ( TS_State.touchDetected ) == 0 )
		  {
			  if ( uc_keuze == 0 )
			  {
				  uc_keuze = 1;
				  uc_Data =  3;
				  WDA_LCD_DrawBitmap((void * ) KNOP_ACTIVE_DATA,x10,y140,KNOP_ACTIVE_DATA_X_PIXEL,KNOP_ACTIVE_DATA_Y_PIXEL ,KNOP_ACTIVE_DATA_FORMAT);
			  }
			  else if ( uc_keuze == 1 )
			  {
				  uc_Data = 0;
				  uc_keuze = 0;
				  WDA_LCD_DrawBitmap((void * ) GLIDER_KNOP_INACTIVE_DATA,x10,y140,BLOCK_KNOP_INACTIVE_DATA_X_PIXEL,BLOCK_KNOP_INACTIVE_DATA_Y_PIXEL ,BLOCK_KNOP_INACTIVE_DATA_FORMAT); // keuzeknop 1
			  }
			  else
			  {

			  }
		  }
		  HAL_Delay(100);
	  }
	  // keuze knop EIGEN
	  if ( ( ( uc_keuze == 0 ) || ( ( uc_Data == 2 ) || ( uc_Data == 7 ) ) )  && ( ( ( ( (TS_State.touchDetected ) && ( TS_State.touchX[0] >= 10 ) ) && ( TS_State.touchX[0] <= 75 ) ) && ( TS_State.touchY[0] >= 180 ) ) && ( TS_State.touchY[0] <= 215 ) ) )
	  {
		  HAL_Delay(100);
		  BSP_TS_GetState(&TS_State);
		  if ( ( TS_State.touchDetected ) == 0 )
		  {
			  if ( uc_keuze == 0 )
			  {
				  uc_keuze = 1;
				  uc_Data =  2;
				  WDA_LCD_DrawBitmap((void * ) KNOP_ACTIVE_DATA,x10,y180,KNOP_ACTIVE_DATA_X_PIXEL,KNOP_ACTIVE_DATA_Y_PIXEL ,KNOP_ACTIVE_DATA_FORMAT); // keuzeknop 1
			  }
			  else if ( uc_keuze == 1 )
			  {
				  uc_keuze = 0;
				  uc_Data = 7;	// speciale in de server
				  WDA_LCD_DrawBitmap((void * ) CUSTOM_KNOP_INACTIVE_DATA,x10,y180,BLOCK_KNOP_INACTIVE_DATA_X_PIXEL,BLOCK_KNOP_INACTIVE_DATA_Y_PIXEL ,BLOCK_KNOP_INACTIVE_DATA_FORMAT); // keuzeknop 1
			  }
			  else
			  {

			  }
		  }
		  HAL_Delay(100);
	  }

	  // keuze knop LWSS
	  if ( ( ( uc_keuze == 0 ) || ( uc_Data == 5 ) ) && ( ( ( ( ( TS_State.touchDetected ) && ( TS_State.touchX[0] >= 10  ) ) && ( TS_State.touchX[0] <= 75 ) ) && ( TS_State.touchY[0] >= 220) ) && ( TS_State.touchY[0] <= 255 ) ) )
	  {
		  HAL_Delay(100);
		  BSP_TS_GetState(&TS_State);
		  if ( (TS_State.touchDetected ) == 0 )
		  {
			  if ( uc_keuze == 0 )
			  {
				  uc_keuze = 1;
				  uc_Data =  5;
				  WDA_LCD_DrawBitmap((void * ) KNOP_ACTIVE_DATA,x10,y220,KNOP_ACTIVE_DATA_X_PIXEL,KNOP_ACTIVE_DATA_Y_PIXEL ,KNOP_ACTIVE_DATA_FORMAT);
			  }
			  else if ( uc_keuze == 1 )
			  {
				  uc_keuze = 0;
				  uc_Data = 0;
				  WDA_LCD_DrawBitmap((void * ) LWSS_KNOP_INACTIVE_DATA,x10,y220,BLOCK_KNOP_INACTIVE_DATA_X_PIXEL,BLOCK_KNOP_INACTIVE_DATA_Y_PIXEL ,BLOCK_KNOP_INACTIVE_DATA_FORMAT);
			  }
			  else
			  {

			  }
		  }
		  HAL_Delay(100);
	  }

	  // keuze knop PULSAR
	  if ( ( ( uc_keuze == 0 ) || ( uc_Data == 4 ) ) && ( ( ( ( ( TS_State.touchDetected ) && ( TS_State.touchX[0] >= 85  ) ) && ( TS_State.touchX[0] <= 145 ) )  && ( TS_State.touchY[0] >= 100 ) ) && ( TS_State.touchY[0] <= 135 ) ) )
	  {

		  HAL_Delay(100);
		  BSP_TS_GetState(&TS_State);
		  if ( ( TS_State.touchDetected ) == 0 )
		  {

			  if ( uc_keuze == 0 )
			  {
				  uc_keuze = 1;
				  uc_Data =  4;
				  WDA_LCD_DrawBitmap((void * ) KNOP_ACTIVE_DATA,x85,y100,KNOP_ACTIVE_DATA_X_PIXEL,KNOP_ACTIVE_DATA_Y_PIXEL ,KNOP_ACTIVE_DATA_FORMAT);
			  }
			  else if ( uc_keuze == 1 )
			  {
				  uc_keuze = 0;
				  uc_Data =  0;
				  WDA_LCD_DrawBitmap((void * ) PULSAR_KNOP_INACTIVE_DATA,x85,y100,BLOCK_KNOP_INACTIVE_DATA_X_PIXEL,BLOCK_KNOP_INACTIVE_DATA_Y_PIXEL ,BLOCK_KNOP_INACTIVE_DATA_FORMAT);
			  }
			  else
			  {

			  }
		  }
		  HAL_Delay(100);
	  }

	  // keuze knop INIT
	  if ( ( ( uc_keuze == 0 ) || ( uc_Data == 6 ) ) && ( ( ( ( TS_State.touchDetected ) && ( TS_State.touchX[0] >= 85  ) ) &&  ( TS_State.touchX[0] <= 145 ) && ( TS_State.touchY[0] >= 140 ) ) && ( TS_State.touchY[0] <= 175 ) ) )
	  {
		  HAL_Delay(100);
		  BSP_TS_GetState(&TS_State);
		  if ( ( TS_State.touchDetected ) == 0 )
		  {
			  if ( uc_keuze == 0 )
			  {
				  uc_keuze = 1;
				  uc_Data =  6;
				  WDA_LCD_DrawBitmap((void * ) KNOP_ACTIVE_DATA,x85,y140,KNOP_ACTIVE_DATA_X_PIXEL,KNOP_ACTIVE_DATA_Y_PIXEL ,KNOP_ACTIVE_DATA_FORMAT);
			  }
			  else if ( uc_keuze == 1 )
			  {
				  uc_Data = 0;
				  uc_keuze = 0;
				  WDA_LCD_DrawBitmap((void * ) INIT_KNOP_INACTIVE_DATA,x85,y140,BLOCK_KNOP_INACTIVE_DATA_X_PIXEL,BLOCK_KNOP_INACTIVE_DATA_Y_PIXEL ,BLOCK_KNOP_INACTIVE_DATA_FORMAT);
			  }
			  else
			  {

			  }
		  }
		  HAL_Delay(100);
	  }
  }
  /* USER CODE END 3 */

}

void SystemClock_Config( void )
{

  RCC_OscInitTypeDef RCC_OscInitStruct;
  RCC_ClkInitTypeDef RCC_ClkInitStruct;
  RCC_PeriphCLKInitTypeDef PeriphClkInitStruct;

    /**Configure the main internal regulator output voltage
    */
  __HAL_RCC_PWR_CLK_ENABLE();

  __HAL_PWR_VOLTAGESCALING_CONFIG(PWR_REGULATOR_VOLTAGE_SCALE1);

    /**Initializes the CPU, AHB and APB busses clocks
    */
  RCC_OscInitStruct.OscillatorType = RCC_OSCILLATORTYPE_HSE;
  RCC_OscInitStruct.HSEState = RCC_HSE_ON;
  RCC_OscInitStruct.PLL.PLLState = RCC_PLL_ON;
  RCC_OscInitStruct.PLL.PLLSource = RCC_PLLSOURCE_HSE;
  RCC_OscInitStruct.PLL.PLLM = 25;
  RCC_OscInitStruct.PLL.PLLN = 400;
  RCC_OscInitStruct.PLL.PLLP = RCC_PLLP_DIV2;
  RCC_OscInitStruct.PLL.PLLQ = 2;
  if (HAL_RCC_OscConfig(&RCC_OscInitStruct) != HAL_OK)
  {
    _Error_Handler(__FILE__, __LINE__);
  }

    /**Activate the Over-Drive mode
    */
  if (HAL_PWREx_EnableOverDrive() != HAL_OK)
  {
    _Error_Handler(__FILE__, __LINE__);
  }

    /**Initializes the CPU, AHB and APB busses clocks
    */
  RCC_ClkInitStruct.ClockType = RCC_CLOCKTYPE_HCLK|RCC_CLOCKTYPE_SYSCLK
                              |RCC_CLOCKTYPE_PCLK1|RCC_CLOCKTYPE_PCLK2;
  RCC_ClkInitStruct.SYSCLKSource = RCC_SYSCLKSOURCE_PLLCLK;
  RCC_ClkInitStruct.AHBCLKDivider = RCC_SYSCLK_DIV1;
  RCC_ClkInitStruct.APB1CLKDivider = RCC_HCLK_DIV4;
  RCC_ClkInitStruct.APB2CLKDivider = RCC_HCLK_DIV2;

  if (HAL_RCC_ClockConfig(&RCC_ClkInitStruct, FLASH_LATENCY_6) != HAL_OK)
  {
    _Error_Handler(__FILE__, __LINE__);
  }

  PeriphClkInitStruct.PeriphClockSelection = RCC_PERIPHCLK_LTDC|RCC_PERIPHCLK_USART1;
  PeriphClkInitStruct.PLLSAI.PLLSAIN = 192;
  PeriphClkInitStruct.PLLSAI.PLLSAIR = 5;
  PeriphClkInitStruct.PLLSAI.PLLSAIQ = 2;
  PeriphClkInitStruct.PLLSAI.PLLSAIP = RCC_PLLSAIP_DIV2;
  PeriphClkInitStruct.PLLSAIDivQ = 1;
  PeriphClkInitStruct.PLLSAIDivR = RCC_PLLSAIDIVR_4;
  PeriphClkInitStruct.Usart1ClockSelection = RCC_USART1CLKSOURCE_PCLK2;
  if (HAL_RCCEx_PeriphCLKConfig(&PeriphClkInitStruct) != HAL_OK)
  {
    _Error_Handler(__FILE__, __LINE__);
  }

    /**Configure the Systick interrupt time
    */
  HAL_SYSTICK_Config(HAL_RCC_GetHCLKFreq()/1000);

    /**Configure the Systick
    */
  HAL_SYSTICK_CLKSourceConfig(SYSTICK_CLKSOURCE_HCLK);

  /* SysTick_IRQn interrupt configuration */
  HAL_NVIC_SetPriority(SysTick_IRQn, 0, 0);
}

/* DMA2D init function */
static void MX_DMA2D_Init( void )
{

  hdma2d.Instance = DMA2D;
  hdma2d.Init.Mode = DMA2D_M2M;
  hdma2d.Init.ColorMode = DMA2D_OUTPUT_ARGB8888;
  hdma2d.Init.OutputOffset = 0;
  hdma2d.LayerCfg[1].InputOffset = 0;
  hdma2d.LayerCfg[1].InputColorMode = DMA2D_INPUT_ARGB8888;
  hdma2d.LayerCfg[1].AlphaMode = DMA2D_NO_MODIF_ALPHA;
  hdma2d.LayerCfg[1].InputAlpha = 0;
  if (HAL_DMA2D_Init(&hdma2d) != HAL_OK)
  {
    _Error_Handler(__FILE__, __LINE__);
  }

  if (HAL_DMA2D_ConfigLayer(&hdma2d, 1) != HAL_OK)
  {
    _Error_Handler(__FILE__, __LINE__);
  }

}

/* LTDC init function */
static void MX_LTDC_Init( void )
{

  LTDC_LayerCfgTypeDef pLayerCfg;
  LTDC_LayerCfgTypeDef pLayerCfg1;

  hltdc.Instance = LTDC;
  hltdc.Init.HSPolarity = LTDC_HSPOLARITY_AL;
  hltdc.Init.VSPolarity = LTDC_VSPOLARITY_AL;
  hltdc.Init.DEPolarity = LTDC_DEPOLARITY_AL;
  hltdc.Init.PCPolarity = LTDC_PCPOLARITY_IPC;
  hltdc.Init.HorizontalSync = 40;
  hltdc.Init.VerticalSync = 9;
  hltdc.Init.AccumulatedHBP = 53;
  hltdc.Init.AccumulatedVBP = 11;
  hltdc.Init.AccumulatedActiveW = 533;
  hltdc.Init.AccumulatedActiveH = 283;
  hltdc.Init.TotalWidth = 565;
  hltdc.Init.TotalHeigh = 285;
  hltdc.Init.Backcolor.Blue = 0;
  hltdc.Init.Backcolor.Green = 255;
  hltdc.Init.Backcolor.Red = 0;
  if (HAL_LTDC_Init(&hltdc) != HAL_OK)
  {
    _Error_Handler(__FILE__, __LINE__);
  }

  pLayerCfg.WindowX0 = 0;
  pLayerCfg.WindowX1 = 480;
  pLayerCfg.WindowY0 = 0;
  pLayerCfg.WindowY1 = 272;
  pLayerCfg.PixelFormat = LTDC_PIXEL_FORMAT_ARGB1555;
  pLayerCfg.Alpha = 255;
  pLayerCfg.Alpha0 = 0;
  pLayerCfg.BlendingFactor1 = LTDC_BLENDING_FACTOR1_PAxCA;
  pLayerCfg.BlendingFactor2 = LTDC_BLENDING_FACTOR2_PAxCA;
  pLayerCfg.FBStartAdress = 0;
  pLayerCfg.ImageWidth = 480;
  pLayerCfg.ImageHeight = 272;
  pLayerCfg.Backcolor.Blue = 0;
  pLayerCfg.Backcolor.Green = 0;
  pLayerCfg.Backcolor.Red = 0;
  if (HAL_LTDC_ConfigLayer(&hltdc, &pLayerCfg, 0) != HAL_OK)
  {
    _Error_Handler(__FILE__, __LINE__);
  }

  pLayerCfg1.WindowX0 = 0;
  pLayerCfg1.WindowX1 = 480;
  pLayerCfg1.WindowY0 = 0;
  pLayerCfg1.WindowY1 = 272;
  pLayerCfg1.PixelFormat = LTDC_PIXEL_FORMAT_ARGB1555;
  pLayerCfg1.Alpha = 255;
  pLayerCfg1.Alpha0 = 0;
  pLayerCfg1.BlendingFactor1 = LTDC_BLENDING_FACTOR1_PAxCA;
  pLayerCfg1.BlendingFactor2 = LTDC_BLENDING_FACTOR2_PAxCA;
  pLayerCfg1.FBStartAdress = 0;
  pLayerCfg1.ImageWidth = 480;
  pLayerCfg1.ImageHeight = 272;
  pLayerCfg1.Backcolor.Blue = 0;
  pLayerCfg1.Backcolor.Green = 0;
  pLayerCfg1.Backcolor.Red = 0;
  if (HAL_LTDC_ConfigLayer(&hltdc, &pLayerCfg1, 1) != HAL_OK)
  {
    _Error_Handler(__FILE__, __LINE__);
  }

}

/* USART1 init function */
static void MX_USART1_UART_Init( void )
{

  huart1.Instance = USART1;
  huart1.Init.BaudRate = 115200;
  huart1.Init.WordLength = UART_WORDLENGTH_8B;
  huart1.Init.StopBits = UART_STOPBITS_1;
  huart1.Init.Parity = UART_PARITY_NONE;
  huart1.Init.Mode = UART_MODE_TX_RX;
  huart1.Init.HwFlowCtl = UART_HWCONTROL_NONE;
  huart1.Init.OverSampling = UART_OVERSAMPLING_16;
  huart1.Init.OneBitSampling = UART_ONE_BIT_SAMPLE_DISABLE;
  huart1.AdvancedInit.AdvFeatureInit = UART_ADVFEATURE_NO_INIT;
  if (HAL_UART_Init(&huart1) != HAL_OK)
  {
    _Error_Handler(__FILE__, __LINE__);
  }

}

/* FMC initialization function */
static void MX_FMC_Init( void )
{
  FMC_SDRAM_TimingTypeDef SdramTiming;

  /** Perform the SDRAM1 memory initialization sequence
  */
  hsdram1.Instance = FMC_SDRAM_DEVICE;
  /* hsdram1.Init */
  hsdram1.Init.SDBank = FMC_SDRAM_BANK1;
  hsdram1.Init.ColumnBitsNumber = FMC_SDRAM_COLUMN_BITS_NUM_8;
  hsdram1.Init.RowBitsNumber = FMC_SDRAM_ROW_BITS_NUM_12;
  hsdram1.Init.MemoryDataWidth = FMC_SDRAM_MEM_BUS_WIDTH_16;
  hsdram1.Init.InternalBankNumber = FMC_SDRAM_INTERN_BANKS_NUM_4;
  hsdram1.Init.CASLatency = FMC_SDRAM_CAS_LATENCY_1;
  hsdram1.Init.WriteProtection = FMC_SDRAM_WRITE_PROTECTION_DISABLE;
  hsdram1.Init.SDClockPeriod = FMC_SDRAM_CLOCK_DISABLE;
  hsdram1.Init.ReadBurst = FMC_SDRAM_RBURST_DISABLE;
  hsdram1.Init.ReadPipeDelay = FMC_SDRAM_RPIPE_DELAY_0;
  /* SdramTiming */
  SdramTiming.LoadToActiveDelay = 16;
  SdramTiming.ExitSelfRefreshDelay = 16;
  SdramTiming.SelfRefreshTime = 16;
  SdramTiming.RowCycleDelay = 16;
  SdramTiming.WriteRecoveryTime = 16;
  SdramTiming.RPDelay = 16;
  SdramTiming.RCDDelay = 16;

  if (HAL_SDRAM_Init(&hsdram1, &SdramTiming) != HAL_OK)
  {
    _Error_Handler(__FILE__, __LINE__);
  }

}

/** Configure pins as
        * Analog
        * Input
        * Output
        * EVENT_OUT
        * EXTI
*/
static void MX_GPIO_Init( void )
{

  GPIO_InitTypeDef GPIO_InitStruct;

  /* GPIO Ports Clock Enable */
  __HAL_RCC_GPIOE_CLK_ENABLE();
  __HAL_RCC_GPIOG_CLK_ENABLE();
  __HAL_RCC_GPIOB_CLK_ENABLE();
  __HAL_RCC_GPIOJ_CLK_ENABLE();
  __HAL_RCC_GPIOD_CLK_ENABLE();
  __HAL_RCC_GPIOK_CLK_ENABLE();
  __HAL_RCC_GPIOF_CLK_ENABLE();
  __HAL_RCC_GPIOI_CLK_ENABLE();
  __HAL_RCC_GPIOC_CLK_ENABLE();
  __HAL_RCC_GPIOA_CLK_ENABLE();
  __HAL_RCC_GPIOH_CLK_ENABLE();

  /*Configure GPIO pin Output Level */
  HAL_GPIO_WritePin(LCD_BL_CTRL_GPIO_Port, LCD_BL_CTRL_Pin, GPIO_PIN_RESET);

  /*Configure GPIO pin Output Level */
  HAL_GPIO_WritePin(GPIOI, LED_Pin|LCD_DISP_Pin, GPIO_PIN_RESET);

  /*Configure GPIO pin : LCD_BL_CTRL_Pin */
  GPIO_InitStruct.Pin = LCD_BL_CTRL_Pin;
  GPIO_InitStruct.Mode = GPIO_MODE_OUTPUT_PP;
  GPIO_InitStruct.Pull = GPIO_NOPULL;
  GPIO_InitStruct.Speed = GPIO_SPEED_FREQ_LOW;
  HAL_GPIO_Init(LCD_BL_CTRL_GPIO_Port, &GPIO_InitStruct);

  /*Configure GPIO pins : LED_Pin LCD_DISP_Pin */
  GPIO_InitStruct.Pin = LED_Pin|LCD_DISP_Pin;
  GPIO_InitStruct.Mode = GPIO_MODE_OUTPUT_PP;
  GPIO_InitStruct.Pull = GPIO_NOPULL;
  GPIO_InitStruct.Speed = GPIO_SPEED_FREQ_LOW;
  HAL_GPIO_Init(GPIOI, &GPIO_InitStruct);

  /*Configure GPIO pin : BUTTON_Pin */
  GPIO_InitStruct.Pin = BUTTON_Pin;
  GPIO_InitStruct.Mode = GPIO_MODE_INPUT;
  GPIO_InitStruct.Pull = GPIO_NOPULL;
  HAL_GPIO_Init(BUTTON_GPIO_Port, &GPIO_InitStruct);

}

void _Error_Handler( char *file, int line )
{
  while(1)
  {
  }
}

/************************ (C) COPYRIGHT STMicroelectronics *****END OF FILE****/
